# M460 register map
File version: 1.0
Registers are 32-bit, read-write, reset 0x0 unless marked. A register's access mark holds for its fields unless they carry their own. Offsets are from the block's base; [hi:lo] are bit positions; {n}, {i} and the like mark numbered series.

## AES — CRYPTO Register Map
Base 0x40032050
{0x0+4i} CRYPTO_AES_FDBCK{i} ro (i=0..3) — AES Engine Output Feedback Data After Cryptographic Operation
  [31:0] FDBCK — AES Feedback Information. The feedback value is 128 bits in size. The AES engine uses the data from CRYPTO_AES_FDBCKx as the data inputted to CRYPTO_AES_IVx for the next block in DMA cascade mode. The AES engine outputs feedback information for IV in the next block's operation. Software can use this feedback information to implement more than four DMA channels. Software can store that feedback value temporarily. After switching back, fill the stored feedback value to CRYPTO_AES_IVx in the same channel operation, and then continue the operation with the original setting.
0x30 CRYPTO_AES_GCM_IVCNT0 — AES GCM IV Byte Count Register 0
  [31:0] CNT — AES GCM IV Byte Count. The bit length of IV is 64 bits for AES GCM mode. The CRYPTO_AES_GCM_IVCNT0 keeps the low weight byte count of initial vector (i.e., len(IV)[34:3]) of AES GCM mode and can be read and written.
0x34 CRYPTO_AES_GCM_IVCNT1 — AES GCM IV Byte Count Register 1
  [28:0] CNT — AES GCM IV Byte Count. The bit length of IV is 64 bits for AES GCM mode. The CRYPTO_AES_GCM_IVCNT1 keeps the high weight byte count of initial vector (i.e., len(IV)[64:35]) of AES GCM mode and can be read and written.
0x38 CRYPTO_AES_GCM_ACNT0 — AES GCM A Byte Count Register 0
  [31:0] CNT — AES GCM a Byte Count. The bit length of A is 64 bits for AES GCM mode. The CRYPTO_AES_GCM_ACNT0 keeps the low weight byte count of the additional authenticated data (i.e., len(A)[34:3]) of AES GCM mode and can be read and written.
0x3C CRYPTO_AES_GCM_ACNT1 — AES GCM A Byte Count Register 1
  [28:0] CNT — AES GCM a Byte Count. The bit length of A is 64 bits for AES GCM mode. The CRYPTO_AES_GCM_ACNT0 keeps the high weight byte count of the additional authenticated data (i.e., len(A)[63:35]) of AES GCM mode and can be read and written.
0x40 CRYPTO_AES_GCM_PCNT0 — AES GCM P Byte Count Register 0
  [31:0] CNT — AES GCM P Byte Count. The bit length of Por C is 39 bits for AES GCM mode. The CRYPTO_AES_GCM_PCNT0 keeps the low weight byte count of the plaintext or ciphertext (i.e., len(P)[34:3] or len(C)[34:3]) of AES GCM mode and can be read and written.
0x44 CRYPTO_AES_GCM_PCNT1 — AES GCM P Byte Count Register 1
  [28:0] CNT — AES GCM P Byte Count. The bit length of Por C is 39 bits for AES GCM mode. The CRYPTO_AES_GCM_PCNT1 keeps the high weight byte count of the plaintext or ciphertext (i.e., len(P)[38:35] or len(C)[38:35]) of AES GCM mode and can be read and written. The bit length of Por C is 64 bits for AES CCM mode. The CRYPTO_AES_GCM_PCNT1 keeps the high weight byte count of the plaintext or ciphertext (i.e., len(P)[63:35] or len(C)[63:35]) of AES CCM mode and can be read and written.
0x50 CRYPTO_AES_FBADDR — AES DMA Feedback Address Register
  [31:0] FBADDR — AES DMA Feedback Address. In DMA cascade mode, software can update DMA feedback address register for automatically reading and writing feedback values via DMA. The FBADDR keeps the feedback address of the feedback data for the next cascade operation. Based on the feedback address, the AES accelerator can read the feedback data of the last cascade operation from SRAM memory space and write the feedback data of the current cascade operation to SRAM memory space. The start of feedback address should be located at word boundary. In other words, bit 1 and 0 of FBADDR are ignored. FBADDR can be read and written. In DMA mode, software can update the next CRYPTO_AES_FBADDR before triggering START.
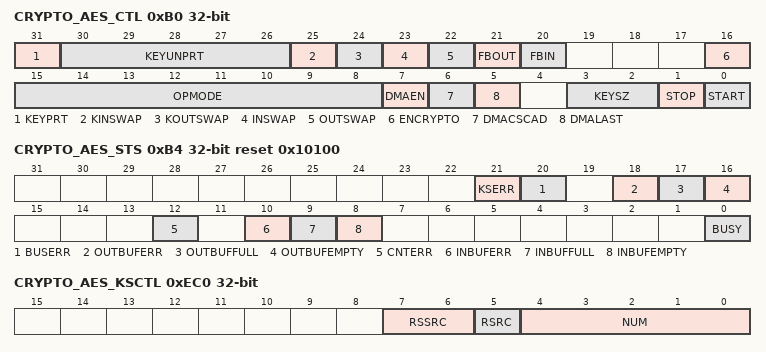
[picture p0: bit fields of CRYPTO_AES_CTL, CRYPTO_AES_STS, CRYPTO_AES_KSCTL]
0xB0 CRYPTO_AES_CTL — AES Control Register
  [31] KEYPRT — Protect Key. Read as a flag to reflect KEYPRT.
    0=No effect; 1=Protect the content of the AES key from reading. The return value for reading CRYPTO_AES_KEYx is not the content of the registers CRYPTO_AES_KEYx. Once it is set, it can be cleared by asserting KEYUNPRT. The key content would be cleared as well
  [30:26] KEYUNPRT — Unprotect Key. Writing 0 to CRYPTO_AES_CTL[31] and '10110' to CRYPTO_AES_CTL[30:26] is to unprotect the AES key. The KEYUNPRT can be read and written. When it is written as the AES engine is operating, BUSY flag is 1, there would be no effect on KEYUNPRT.
  [25] KINSWAP — AES Engine Input Key and Initial Vector Swap
    0=Keep the original order; 1=The order that CPU feeds key and initial vector to the accelerator will be changed from {byte3, byte2, byte1, byte0} to {byte0, byte1, byte2, byte3}
  [24] KOUTSWAP — AES Engine Output Key, Initial Vector and Feedback Swap
    0=Keep the original order; 1=The order that CPU reads key, initial vector and feedback from the accelerator will be changed from {byte3, byte2, byte1, byte0} to {byte0, byte1, byte2, byte3}
  [23] INSWAP — AES Engine Input Data Swap
    0=Keep the original order; 1=The order that CPU feeds data to the accelerator will be changed from {byte3, byte2, byte1, byte0} to {byte0, byte1, byte2, byte3}
  [22] OUTSWAP — AES Engine Output Data Swap
    0=Keep the original order; 1=The order that CPU reads data from the accelerator will be changed from {byte3, byte2, byte1, byte0} to {byte0, byte1, byte2, byte3}
  [21] FBOUT — Feedback Output From AES Via DMA Automatically
    0=DMA automatic feedback output function Disabled; 1=DMA automatic feedback output function Enabled when DMAEN = 1
  [20] FBIN — Feedback Input to AES Via DMA Automatically
    0=DMA automatic feedback input function Disabled; 1=DMA automatic feedback input function Enabled when DMAEN = 1
  [16] ENCRYPTO — AES Encryption/Decryption
    0=AES engine executes decryption operation; 1=AES engine executes encryption operation
  [15:8] OPMODE — AES Engine Operation Modes
    0=ECB (Electronic Codebook Mode) 0x01 = CBC (Cipher Block Chaining Mode); 2=CFB (Cipher Feedback Mode); 3=OFB (Output Feedback Mode); 4=CTR (Counter Mode); 16=CBC-CS1 (CBC Ciphertext-Stealing 1 Mode); 17=CBC-CS2 (CBC Ciphertext-Stealing 2 Mode); 18=CBC-CS3 (CBC Ciphertext-Stealing 3 Mode); 32=GCM (Galois/Counter Mode); 33=GHASH (Galois Hash Function); 34=CCM (Counter with CBC-MAC Mode)
  [7] DMAEN — AES Engine DMA Enable Bit. The AES engine operates in DMA mode, and data movement from/to the engine is done by DMA logic.
    0=AES DMA engine Disabled; 1=AES_DMA engine Enabled
  [6] DMACSCAD — AES Engine DMA with Cascade Mode. Note: The last two blocks of AES-CBC-CS1/2/3 must be in the last cascade operation.
    0=DMA cascade function Disabled; 1=In DMA cascade mode, software can update DMA source address register, destination address register, and byte count register during a cascade operation, without finishing the accelerator operation
  [5] DMALAST — AES Last Block. In DMA mode, this bit must be set as beginning the last DMA cascade round. In Non-DMA mode, this bit must be set when feeding in the last block of data in ECB, CBC, CTR, OFB, and CFB mode, and feeding in the (last-1) block of data at CBC-CS1, CBC-CS2, and CBC-CS3 mode. This bit is always 0 when it is read back, and must be written again once START is triggered.
  [3:2] KEYSZ — AES Key Size. This bit defines three different key size for AES operation. If the AES accelerator is operating and the corresponding flag BUSY is 1, updating this register has no effect.
  [1] STOP — AES Engine Stop. Note: This bit is always 0 when it is read back.
    0=No effect; 1=Stop AES engine
  [0] START — AES Engine Start. Note: This bit is always 0 when it is read back.
    0=No effect; 1=Start AES engine. BUSY flag will be set
0xB4 CRYPTO_AES_STS ro reset 0x10100 — AES Engine Flag
  [21] KSERR — AES Engine Access Key Store Error Flag
    0=No error; 1=Key store access error will stop AES engine
  [20] BUSERR — AES DMA Access Bus Error Flag
    0=No error; 1=Bus error will stop DMA operation and AES engine
  [18] OUTBUFERR — AES Out Buffer Error Flag
    0=No error; 1=Error happened during getting the result from AES engine
  [17] OUTBUFFULL — AES Out Buffer Full Flag
    0=AES output buffer is not full; 1=AES output buffer is full, and software needs to get data from CRYPTO_AES_DATOUT. Otherwise, the AES engine will be pending since the output buffer is full
  [16] OUTBUFEMPTY — AES Out Buffer Empty
    0=AES output buffer is not empty. There are some valid data kept in output buffer; 1=AES output buffer is empty. Software cannot get data from CRYPTO_AES_DATOUT. Otherwise, the flag OUTBUFERR will be set to 1 since the output buffer is empty
  [12] CNTERR — CRYPTO_AES_CNT Setting Error
    0=No error in CRYPTO_AES_CNT setting; 1=CRYPTO_AES_CNT is 0 if DMAEN (CRYPTO_AES_CTL[7]) is enabled
  [10] INBUFERR — AES Input Buffer Error Flag
    0=No error; 1=Error happened during feeding data to the AES engine
  [9] INBUFFULL — AES Input Buffer Full Flag
    0=AES input buffer is not full. Software can feed the data into the AES engine; 1=AES input buffer is full. Software cannot feed data to the AES engine. Otherwise, the flag INBUFERR will be set to 1
  [8] INBUFEMPTY — AES Input Buffer Empty
    0=There are some data in input buffer waiting for the AES engine to process; 1=AES input buffer is empty. Software needs to feed data to the AES engine. Otherwise, the AES engine will be pending to wait for input data
  [0] BUSY — AES Engine Busy
    0=The AES engine is idle or finished; 1=The AES engine is under processing
0xB8 CRYPTO_AES_DATIN — AES Engine Data Input Port Register
  [31:0] DATIN — AES Engine Input Port. CPU feeds data to AES engine through this port by checking CRYPTO_AES_STS. Feed data as INBUFFULL is 0.
0xBC CRYPTO_AES_DATOUT ro — AES Engine Data Output Port Register
  [31:0] DATOUT — AES Engine Output Port. CPU gets results from the AES engine through this port by checking CRYPTO_AES_STS. Get data as OUTBUFEMPTY is 0.
{0xC0+4i} CRYPTO_AES_KEY{i} (i=0..7) — AES Key Word {i} Register
  [31:0] KEY — CRYPTO_AES_KEYx. The KEY keeps the security key for AES operation. The security key for AES accelerator can be 128, 192, or 256 bits and four, six, or eight 32-bit registers are to store each security key. {CRYPTO_AES_KEY3, CRYPTO_AES_KEY2, CRYPTO_AES_KEY1, CRYPTO_AES_KEY0} stores the 128-bit security key for AES operation. {CRYPTO_AES_KEY5, CRYPTO_AES_KEY4, CRYPTO_AES_KEY3, CRYPTO_AES_KEY2, CRYPTO_AES_KEY1, CRYPTO_AES_KEY0} stores the 192-bit security key for AES operation. {CRYPTO_AES_KEY7, CRYPTO_AES_KEY6, CRYPTO_AES_KEY5, CRYPTO_AES_KEY4, CRYPTO_AES_KEY3, CRYPTO_AES_KEY2, CRYPTO_AES_KEY1, CRYPTO_AES_KEY0} stores the 256-bit security key for AES operation.
{0xE0+4i} CRYPTO_AES_IV{i} (i=0..3) — AES Initial Vector Word {i} Register
  [31:0] IV — AES Initial Vectors. Four initial vectors (CRYPTO_AES_IV0, CRYPTO_AES_IV1, CRYPTO_AES_IV2, and CRYPTO_AES_IV3) are for AES operating in CBC, CFB, and OFB mode. Four registers (CRYPTO_AES_IV0, CRYPTO_AES_IV1, CRYPTO_AES_IV2, and CRYPTO_AES_IV3) act as Nonce counter when the AES engine is operating in CTR mode.
0xF0 CRYPTO_AES_SADDR — AES DMA Source Address Register
  [31:0] SADDR — AES DMA Source Address. The AES accelerator supports DMA function to transfer the plain text between SRAM memory space and embedded FIFO. The SADDR keeps the source address of the data buffer where the source text is stored. Based on the source address, the AES accelerator can read the plain text (encryption) / cipher text (decryption) from SRAM memory space and do AES operation. The start of source address should be located at word boundary. In other words, bit 1 and 0 of SADDR are ignored. SADDR can be read and written. Writing to SADDR while the AES accelerator is operating doesn't affect the current AES operation. But the value of SADDR will be updated later on. Consequently, software can prepare the DMA source address for the next AES operation. In DMA mode, software can update the next CRYPTO_AES_SADDR before triggering START. The value of CRYPTO_AES_SADDR and CRYPTO_AES_DADDR can be the same.
0xF4 CRYPTO_AES_DADDR — AES DMA Destination Address Register
  [31:0] DADDR — AES DMA Destination Address. The AES accelerator supports DMA function to transfer the cipher text between SRAM memory space and embedded FIFO. The DADDR keeps the destination address of the data buffer where the engine output's text will be stored. Based on the destination address, the AES accelerator can write the cipher text (encryption) / plain text (decryption) back to SRAM memory space after the AES operation is finished. The start of destination address should be located at word boundary. In other words, bit 1 and 0 of DADDR are ignored. DADDR can be read and written. Writing to DADDR while the AES accelerator is operating doesn't affect the current AES operation. But the value of DADDR will be updated later on. Consequently, software can prepare the destination address for the next AES operation. In DMA mode, software can update the next CRYPTO_AES_DADDR before triggering START. The value of CRYPTO_AES_SADDR and CRYPTO_AES_DADDR can be the same.
0xF8 CRYPTO_AES_CNT — AES Byte Count Register
  [31:0] CNT — AES Byte Count. The CRYPTO_AES_CNT keeps the byte count of source text that is for the AES engine operating in DMA mode. The CRYPTO_AES_CNT is 32-bit and the maximum of byte count is 4G bytes. CRYPTO_AES_CNT can be read and written. Writing to CRYPTO_AES_CNT while the AES accelerator is operating doesn't affect the current AES operation. But the value of CRYPTO_AES_CNT will be updated later on. Consequently, software can prepare the byte count of data for the next AES operation. According to CBC-CS1, CBC-CS2, and CBC-CS3 standard, the count of operation data must be more than 16 bytes. Operations that are equal to or less than one block will output unexpected result. In Non-DMA ECB, CBC, CFB, OFB, CTR, CCM and GCM mode, CRYPTO_AES_CNT must be set as byte count for the last block of data before feeding in the last block of data. In Non-DMA CBC-CS1, CBC-CS2, and CBC-CS3 mode, CRYPTO_AES_CNT must be set as byte count for the last two blocks of data before feeding in the last two blocks of data. In AES GCM mode without DMA cascade function, the value of CRYPTO_AES_CNT is equal to the total value of {CRYPTO_AES_GCM_IVCNT1, CRYPTO_AES_GCM_IVCNT0}, {CRYPTO_AES_GCM_ACNT1, CRYPTO_AES_GCM_ACNT0} and {CRYPTO_AES_GCM_PCNT1, CRYPTO_AES_GCM_PCNT0}. In AES GCM mode with DMA cascade function, the value of CRYPTO_AES_CNT represents the byte count of source text in this cascade function. Thus, the value of CRYPTO_AES_CNT is less than or equal to the total value of {CRYPTO_AES_GCM_IVCNT1, CRYPTO_AES_GCM_IVCNT0}, {CRYPTO_AES_GCM_ACNT1, CRYPTO_AES_GCM_ACNT0} and {CRYPTO_AES_GCM_PCNT1, CRYPTO_AES_GCM_PCNT0} and must be block alignment. In AES CCM mode without DMA cascade function, the value of CRYPTO_AES_CNT is equal to the total value of {CRYPTO_AES_GCM_ACNT1, CRYPTO_AES_GCM_ACNT0} and {CRYPTO_AES_GCM_PCNT1, CRYPTO_AES_GCM_PCNT0}. In AES CCM mode with DMA cascade function, the value of CRYPTO_AES_CNT represents the byte count of source text in this cascade function. Thus, the value of CRYPTO_AES_CNT is less than or equal to the total value of {CRYPTO_AES_GCM_ACNT1, CRYPTO_AES_GCM_ACNT0} and {CRYPTO_AES_GCM_PCNT1, CRYPTO_AES_GCM_PCNT0} and must be block alignment, except for the last block of plaintext or ciphertext.
0xEC0 CRYPTO_AES_KSCTL wo — AES Key Control Register
  [7:6] RSSRC — Read Key Store Source
    0=Key is read from the SRAM of key store; 1=Key is read from the Flash of key store; 2=Key is read from the OTP of key store
  [5] RSRC — Read Key Source
    0=Key is read from registers CRYPTO_AESx_KEYx; 1=Key is read from key store
  [4:0] NUM — Read Key Number. The key number is sent to key store
